# ior7f701057 register map
Registers are 8-bit, access not given, no defined reset value unless marked. A register's access mark holds for its fields unless they carry their own. Addresses are absolute; registers are grouped by the start of their names; [hi:lo] are bit positions; {n}, {i} and the like mark numbered series; 'fields as' and 'values as' point back to an identical list.

## SFR (part 2 of 3)
{0xFFD00E80+0x10*i} RSCAN0CFID{i}LL (i=0..17)
{0xFFD00E81+0x10*i} RSCAN0CFID{i}LH (i=0..17)
{0xFFD00E82+0x10*i} RSCAN0CFID{i}H 16-bit (i=0..17)
{0xFFD00E82+0x10*i} RSCAN0CFID{i}HL (i=0..17)
{0xFFD00E83+0x10*i} RSCAN0CFID{i}HH (i=0..17)
{0xFFD00E84+0x10*i} RSCAN0CFPTR{i} 32-bit (i=0..17)
{0xFFD00E84+0x10*i} RSCAN0CFPTR{i}L 16-bit (i=0..17)
{0xFFD00E84+0x10*i} RSCAN0CFPTR{i}LL (i=0..17)
{0xFFD00E85+0x10*i} RSCAN0CFPTR{i}LH (i=0..17)
{0xFFD00E86+0x10*i} RSCAN0CFPTR{i}H 16-bit (i=0..17)
{0xFFD00E86+0x10*i} RSCAN0CFPTR{i}HL (i=0..17)
{0xFFD00E87+0x10*i} RSCAN0CFPTR{i}HH (i=0..17)
{0xFFD00E88+0x10*i} RSCAN0CFDF{i:02} 32-bit (i=0..9)
{0xFFD00E88+0x10*i} RSCAN0CFDF{i:02}L 16-bit (i=0..9)
{0xFFD00E88+0x10*i} RSCAN0CFDF{i:02}LL (i=0..9)
{0xFFD00E89+0x10*i} RSCAN0CFDF{i:02}LH (i=0..9)
{0xFFD00E8A+0x10*i} RSCAN0CFDF{i:02}H 16-bit (i=0..9)
{0xFFD00E8A+0x10*i} RSCAN0CFDF{i:02}HL (i=0..9)
{0xFFD00E8B+0x10*i} RSCAN0CFDF{i:02}HH (i=0..9)
0xFFD00E8C RSCAN0CFDF10 32-bit
0xFFD00E8C RSCAN0CFDF10L 16-bit
0xFFD00E8C RSCAN0CFDF10LL
0xFFD00E8D RSCAN0CFDF10LH
0xFFD00E8E RSCAN0CFDF10H 16-bit
0xFFD00E8E RSCAN0CFDF10HL
0xFFD00E8F RSCAN0CFDF10HH
0xFFD00E9C RSCAN0CFDF11 32-bit
0xFFD00E9C RSCAN0CFDF11L 16-bit
0xFFD00E9C RSCAN0CFDF11LL
0xFFD00E9D RSCAN0CFDF11LH
0xFFD00E9E RSCAN0CFDF11H 16-bit
0xFFD00E9E RSCAN0CFDF11HL
0xFFD00E9F RSCAN0CFDF11HH
0xFFD00EAC RSCAN0CFDF12 32-bit
0xFFD00EAC RSCAN0CFDF12L 16-bit
0xFFD00EAC RSCAN0CFDF12LL
0xFFD00EAD RSCAN0CFDF12LH
0xFFD00EAE RSCAN0CFDF12H 16-bit
0xFFD00EAE RSCAN0CFDF12HL
0xFFD00EAF RSCAN0CFDF12HH
0xFFD00EBC RSCAN0CFDF13 32-bit
0xFFD00EBC RSCAN0CFDF13L 16-bit
0xFFD00EBC RSCAN0CFDF13LL
0xFFD00EBD RSCAN0CFDF13LH
0xFFD00EBE RSCAN0CFDF13H 16-bit
0xFFD00EBE RSCAN0CFDF13HL
0xFFD00EBF RSCAN0CFDF13HH
0xFFD00ECC RSCAN0CFDF14 32-bit
0xFFD00ECC RSCAN0CFDF14L 16-bit
0xFFD00ECC RSCAN0CFDF14LL
0xFFD00ECD RSCAN0CFDF14LH
0xFFD00ECE RSCAN0CFDF14H 16-bit
0xFFD00ECE RSCAN0CFDF14HL
0xFFD00ECF RSCAN0CFDF14HH
0xFFD00EDC RSCAN0CFDF15 32-bit
0xFFD00EDC RSCAN0CFDF15L 16-bit
0xFFD00EDC RSCAN0CFDF15LL
0xFFD00EDD RSCAN0CFDF15LH
0xFFD00EDE RSCAN0CFDF15H 16-bit
0xFFD00EDE RSCAN0CFDF15HL
0xFFD00EDF RSCAN0CFDF15HH
0xFFD00EEC RSCAN0CFDF16 32-bit
0xFFD00EEC RSCAN0CFDF16L 16-bit
0xFFD00EEC RSCAN0CFDF16LL
0xFFD00EED RSCAN0CFDF16LH
0xFFD00EEE RSCAN0CFDF16H 16-bit
0xFFD00EEE RSCAN0CFDF16HL
0xFFD00EEF RSCAN0CFDF16HH
0xFFD00EFC RSCAN0CFDF17 32-bit
0xFFD00EFC RSCAN0CFDF17L 16-bit
0xFFD00EFC RSCAN0CFDF17LL
0xFFD00EFD RSCAN0CFDF17LH
0xFFD00EFE RSCAN0CFDF17H 16-bit
0xFFD00EFE RSCAN0CFDF17HL
0xFFD00EFF RSCAN0CFDF17HH
0xFFD00F0C RSCAN0CFDF18 32-bit
0xFFD00F0C RSCAN0CFDF18L 16-bit
0xFFD00F0C RSCAN0CFDF18LL
0xFFD00F0D RSCAN0CFDF18LH
0xFFD00F0E RSCAN0CFDF18H 16-bit
0xFFD00F0E RSCAN0CFDF18HL
0xFFD00F0F RSCAN0CFDF18HH
0xFFD00F1C RSCAN0CFDF19 32-bit
0xFFD00F1C RSCAN0CFDF19L 16-bit
0xFFD00F1C RSCAN0CFDF19LL
0xFFD00F1D RSCAN0CFDF19LH
0xFFD00F1E RSCAN0CFDF19H 16-bit
0xFFD00F1E RSCAN0CFDF19HL
0xFFD00F1F RSCAN0CFDF19HH
0xFFD00F28 RSCAN0CFDF010 32-bit
0xFFD00F28 RSCAN0CFDF010L 16-bit
0xFFD00F28 RSCAN0CFDF010LL
0xFFD00F29 RSCAN0CFDF010LH
0xFFD00F2A RSCAN0CFDF010H 16-bit
0xFFD00F2A RSCAN0CFDF010HL
0xFFD00F2B RSCAN0CFDF010HH
{0xFFD0084C+0x10*i} RSCAN0CFDF{i} 32-bit (i=110..117)
{0xFFD0084C+0x10*i} RSCAN0CFDF{i}L 16-bit (i=110..117)
{0xFFD0084C+0x10*i} RSCAN0CFDF{i}LL (i=110..117)
{0xFFD0084D+0x10*i} RSCAN0CFDF{i}LH (i=110..117)
{0xFFD0084E+0x10*i} RSCAN0CFDF{i}H 16-bit (i=110..117)
{0xFFD0084E+0x10*i} RSCAN0CFDF{i}HL (i=110..117)
{0xFFD0084F+0x10*i} RSCAN0CFDF{i}HH (i=110..117)
0xFFD00F38 RSCAN0CFDF011 32-bit
0xFFD00F38 RSCAN0CFDF011L 16-bit
0xFFD00F38 RSCAN0CFDF011LL
0xFFD00F39 RSCAN0CFDF011LH
0xFFD00F3A RSCAN0CFDF011H 16-bit
0xFFD00F3A RSCAN0CFDF011HL
0xFFD00F3B RSCAN0CFDF011HH
0xFFD00F48 RSCAN0CFDF012 32-bit
0xFFD00F48 RSCAN0CFDF012L 16-bit
0xFFD00F48 RSCAN0CFDF012LL
0xFFD00F49 RSCAN0CFDF012LH
0xFFD00F4A RSCAN0CFDF012H 16-bit
0xFFD00F4A RSCAN0CFDF012HL
0xFFD00F4B RSCAN0CFDF012HH
0xFFD00F58 RSCAN0CFDF013 32-bit
0xFFD00F58 RSCAN0CFDF013L 16-bit
0xFFD00F58 RSCAN0CFDF013LL
0xFFD00F59 RSCAN0CFDF013LH
0xFFD00F5A RSCAN0CFDF013H 16-bit
0xFFD00F5A RSCAN0CFDF013HL
0xFFD00F5B RSCAN0CFDF013HH
0xFFD00F68 RSCAN0CFDF014 32-bit
0xFFD00F68 RSCAN0CFDF014L 16-bit
0xFFD00F68 RSCAN0CFDF014LL
0xFFD00F69 RSCAN0CFDF014LH
0xFFD00F6A RSCAN0CFDF014H 16-bit
0xFFD00F6A RSCAN0CFDF014HL
0xFFD00F6B RSCAN0CFDF014HH
0xFFD00F78 RSCAN0CFDF015 32-bit
0xFFD00F78 RSCAN0CFDF015L 16-bit
0xFFD00F78 RSCAN0CFDF015LL
0xFFD00F79 RSCAN0CFDF015LH
0xFFD00F7A RSCAN0CFDF015H 16-bit
0xFFD00F7A RSCAN0CFDF015HL
0xFFD00F7B RSCAN0CFDF015HH
0xFFD00F88 RSCAN0CFDF016 32-bit
0xFFD00F88 RSCAN0CFDF016L 16-bit
0xFFD00F88 RSCAN0CFDF016LL
0xFFD00F89 RSCAN0CFDF016LH
0xFFD00F8A RSCAN0CFDF016H 16-bit
0xFFD00F8A RSCAN0CFDF016HL
0xFFD00F8B RSCAN0CFDF016HH
0xFFD00F98 RSCAN0CFDF017 32-bit
0xFFD00F98 RSCAN0CFDF017L 16-bit
0xFFD00F98 RSCAN0CFDF017LL
0xFFD00F99 RSCAN0CFDF017LH
0xFFD00F9A RSCAN0CFDF017H 16-bit
0xFFD00F9A RSCAN0CFDF017HL
0xFFD00F9B RSCAN0CFDF017HH
{0xFFD01000+0x10*i} RSCAN0TMID{i} 32-bit (i=0..95)
{0xFFD01000+0x10*i} RSCAN0TMID{i}L 16-bit (i=0..95)
{0xFFD01000+0x10*i} RSCAN0TMID{i}LL (i=0..95)
{0xFFD01001+0x10*i} RSCAN0TMID{i}LH (i=0..95)
{0xFFD01002+0x10*i} RSCAN0TMID{i}H 16-bit (i=0..95)
{0xFFD01002+0x10*i} RSCAN0TMID{i}HL (i=0..95)
{0xFFD01003+0x10*i} RSCAN0TMID{i}HH (i=0..95)
{0xFFD01004+0x10*i} RSCAN0TMPTR{i} 32-bit (i=0..95)
{0xFFD01006+0x10*i} RSCAN0TMPTR{i}H 16-bit (i=0..95)
{0xFFD01006+0x10*i} RSCAN0TMPTR{i}HL (i=0..95)
{0xFFD01007+0x10*i} RSCAN0TMPTR{i}HH (i=0..95)
{0xFFD01008+0x10*i} RSCAN0TMDF{i:02} 32-bit (i=0..9)
{0xFFD01008+0x10*i} RSCAN0TMDF{i:02}L 16-bit (i=0..9)
{0xFFD01008+0x10*i} RSCAN0TMDF{i:02}LL (i=0..9)
{0xFFD01009+0x10*i} RSCAN0TMDF{i:02}LH (i=0..9)
{0xFFD0100A+0x10*i} RSCAN0TMDF{i:02}H 16-bit (i=0..9)
{0xFFD0100A+0x10*i} RSCAN0TMDF{i:02}HL (i=0..9)
{0xFFD0100B+0x10*i} RSCAN0TMDF{i:02}HH (i=0..9)
0xFFD0100C RSCAN0TMDF10 32-bit
0xFFD0100C RSCAN0TMDF10L 16-bit
0xFFD0100C RSCAN0TMDF10LL
0xFFD0100D RSCAN0TMDF10LH
0xFFD0100E RSCAN0TMDF10H 16-bit
0xFFD0100E RSCAN0TMDF10HL
0xFFD0100F RSCAN0TMDF10HH
0xFFD0101C RSCAN0TMDF11 32-bit
0xFFD0101C RSCAN0TMDF11L 16-bit
0xFFD0101C RSCAN0TMDF11LL
0xFFD0101D RSCAN0TMDF11LH
0xFFD0101E RSCAN0TMDF11H 16-bit
0xFFD0101E RSCAN0TMDF11HL
0xFFD0101F RSCAN0TMDF11HH
0xFFD0102C RSCAN0TMDF12 32-bit
0xFFD0102C RSCAN0TMDF12L 16-bit
0xFFD0102C RSCAN0TMDF12LL
0xFFD0102D RSCAN0TMDF12LH
0xFFD0102E RSCAN0TMDF12H 16-bit
0xFFD0102E RSCAN0TMDF12HL
0xFFD0102F RSCAN0TMDF12HH
0xFFD0103C RSCAN0TMDF13 32-bit
0xFFD0103C RSCAN0TMDF13L 16-bit
0xFFD0103C RSCAN0TMDF13LL
0xFFD0103D RSCAN0TMDF13LH
0xFFD0103E RSCAN0TMDF13H 16-bit
0xFFD0103E RSCAN0TMDF13HL
0xFFD0103F RSCAN0TMDF13HH
0xFFD0104C RSCAN0TMDF14 32-bit
0xFFD0104C RSCAN0TMDF14L 16-bit
0xFFD0104C RSCAN0TMDF14LL
0xFFD0104D RSCAN0TMDF14LH
0xFFD0104E RSCAN0TMDF14H 16-bit
0xFFD0104E RSCAN0TMDF14HL
0xFFD0104F RSCAN0TMDF14HH
0xFFD0105C RSCAN0TMDF15 32-bit
0xFFD0105C RSCAN0TMDF15L 16-bit
0xFFD0105C RSCAN0TMDF15LL
0xFFD0105D RSCAN0TMDF15LH
0xFFD0105E RSCAN0TMDF15H 16-bit
0xFFD0105E RSCAN0TMDF15HL
0xFFD0105F RSCAN0TMDF15HH
0xFFD0106C RSCAN0TMDF16 32-bit
0xFFD0106C RSCAN0TMDF16L 16-bit
0xFFD0106C RSCAN0TMDF16LL
0xFFD0106D RSCAN0TMDF16LH
0xFFD0106E RSCAN0TMDF16H 16-bit
0xFFD0106E RSCAN0TMDF16HL
0xFFD0106F RSCAN0TMDF16HH
0xFFD0107C RSCAN0TMDF17 32-bit
0xFFD0107C RSCAN0TMDF17L 16-bit
0xFFD0107C RSCAN0TMDF17LL
0xFFD0107D RSCAN0TMDF17LH
0xFFD0107E RSCAN0TMDF17H 16-bit
0xFFD0107E RSCAN0TMDF17HL
0xFFD0107F RSCAN0TMDF17HH
0xFFD0108C RSCAN0TMDF18 32-bit
0xFFD0108C RSCAN0TMDF18L 16-bit
0xFFD0108C RSCAN0TMDF18LL
0xFFD0108D RSCAN0TMDF18LH
0xFFD0108E RSCAN0TMDF18H 16-bit
0xFFD0108E RSCAN0TMDF18HL
0xFFD0108F RSCAN0TMDF18HH
0xFFD0109C RSCAN0TMDF19 32-bit
0xFFD0109C RSCAN0TMDF19L 16-bit
0xFFD0109C RSCAN0TMDF19LL
0xFFD0109D RSCAN0TMDF19LH
0xFFD0109E RSCAN0TMDF19H 16-bit
0xFFD0109E RSCAN0TMDF19HL
0xFFD0109F RSCAN0TMDF19HH
0xFFD010A8 RSCAN0TMDF010 32-bit
0xFFD010A8 RSCAN0TMDF010L 16-bit
0xFFD010A8 RSCAN0TMDF010LL
0xFFD010A9 RSCAN0TMDF010LH
0xFFD010AA RSCAN0TMDF010H 16-bit
0xFFD010AA RSCAN0TMDF010HL
0xFFD010AB RSCAN0TMDF010HH
{0xFFD009CC+0x10*i} RSCAN0TMDF{i} 32-bit (i=110..195)
{0xFFD009CC+0x10*i} RSCAN0TMDF{i}L 16-bit (i=110..195)
{0xFFD009CC+0x10*i} RSCAN0TMDF{i}LL (i=110..195)
{0xFFD009CD+0x10*i} RSCAN0TMDF{i}LH (i=110..195)
{0xFFD009CE+0x10*i} RSCAN0TMDF{i}H 16-bit (i=110..195)
{0xFFD009CE+0x10*i} RSCAN0TMDF{i}HL (i=110..195)
{0xFFD009CF+0x10*i} RSCAN0TMDF{i}HH (i=110..195)
0xFFD010B8 RSCAN0TMDF011 32-bit
0xFFD010B8 RSCAN0TMDF011L 16-bit
0xFFD010B8 RSCAN0TMDF011LL
0xFFD010B9 RSCAN0TMDF011LH
0xFFD010BA RSCAN0TMDF011H 16-bit
0xFFD010BA RSCAN0TMDF011HL
0xFFD010BB RSCAN0TMDF011HH
0xFFD010C8 RSCAN0TMDF012 32-bit
0xFFD010C8 RSCAN0TMDF012L 16-bit
0xFFD010C8 RSCAN0TMDF012LL
0xFFD010C9 RSCAN0TMDF012LH
0xFFD010CA RSCAN0TMDF012H 16-bit
0xFFD010CA RSCAN0TMDF012HL
0xFFD010CB RSCAN0TMDF012HH
0xFFD010D8 RSCAN0TMDF013 32-bit
0xFFD010D8 RSCAN0TMDF013L 16-bit
0xFFD010D8 RSCAN0TMDF013LL
0xFFD010D9 RSCAN0TMDF013LH
0xFFD010DA RSCAN0TMDF013H 16-bit
0xFFD010DA RSCAN0TMDF013HL
0xFFD010DB RSCAN0TMDF013HH
0xFFD010E8 RSCAN0TMDF014 32-bit
0xFFD010E8 RSCAN0TMDF014L 16-bit
0xFFD010E8 RSCAN0TMDF014LL
0xFFD010E9 RSCAN0TMDF014LH
0xFFD010EA RSCAN0TMDF014H 16-bit
0xFFD010EA RSCAN0TMDF014HL
0xFFD010EB RSCAN0TMDF014HH
0xFFD010F8 RSCAN0TMDF015 32-bit
0xFFD010F8 RSCAN0TMDF015L 16-bit
0xFFD010F8 RSCAN0TMDF015LL
0xFFD010F9 RSCAN0TMDF015LH
0xFFD010FA RSCAN0TMDF015H 16-bit
0xFFD010FA RSCAN0TMDF015HL
0xFFD010FB RSCAN0TMDF015HH
0xFFD01108 RSCAN0TMDF016 32-bit
0xFFD01108 RSCAN0TMDF016L 16-bit
0xFFD01108 RSCAN0TMDF016LL
0xFFD01109 RSCAN0TMDF016LH
0xFFD0110A RSCAN0TMDF016H 16-bit
0xFFD0110A RSCAN0TMDF016HL
0xFFD0110B RSCAN0TMDF016HH
0xFFD01118 RSCAN0TMDF017 32-bit
0xFFD01118 RSCAN0TMDF017L 16-bit
0xFFD01118 RSCAN0TMDF017LL
0xFFD01119 RSCAN0TMDF017LH
0xFFD0111A RSCAN0TMDF017H 16-bit
0xFFD0111A RSCAN0TMDF017HL
0xFFD0111B RSCAN0TMDF017HH
0xFFD01128 RSCAN0TMDF018 32-bit
0xFFD01128 RSCAN0TMDF018L 16-bit
0xFFD01128 RSCAN0TMDF018LL
0xFFD01129 RSCAN0TMDF018LH
0xFFD0112A RSCAN0TMDF018H 16-bit
0xFFD0112A RSCAN0TMDF018HL
0xFFD0112B RSCAN0TMDF018HH
{0xFFD01008+0x10*i} RSCAN0TMDF{i:03} 32-bit (i=19..95)
{0xFFD01008+0x10*i} RSCAN0TMDF{i:03}L 16-bit (i=19..95)
{0xFFD01008+0x10*i} RSCAN0TMDF{i:03}LL (i=19..95)
{0xFFD01009+0x10*i} RSCAN0TMDF{i:03}LH (i=19..95)
{0xFFD0100A+0x10*i} RSCAN0TMDF{i:03}H 16-bit (i=19..95)
{0xFFD0100A+0x10*i} RSCAN0TMDF{i:03}HL (i=19..95)
{0xFFD0100B+0x10*i} RSCAN0TMDF{i:03}HH (i=19..95)
{0xFFD01800+4i} RSCAN0THLACC{i} 32-bit ro (i=0..5)
{0xFFD01800+4i} RSCAN0THLACC{i}L 16-bit ro (i=0..5)
{0xFFD01800+4i} RSCAN0THLACC{i}LL ro (i=0..5)
{0xFFD01801+4i} RSCAN0THLACC{i}LH ro (i=0..5)
{0xFFD01900+4i} RSCAN0RPGACC{i} 32-bit (i=0..63)
{0xFFD01900+4i} RSCAN0RPGACC{i}L 16-bit (i=0..63)
{0xFFD01900+4i} RSCAN0RPGACC{i}LL (i=0..63)
{0xFFD01901+4i} RSCAN0RPGACC{i}LH (i=0..63)
{0xFFD01902+4i} RSCAN0RPGACC{i}H 16-bit (i=0..63)
{0xFFD01902+4i} RSCAN0RPGACC{i}HL (i=0..63)
{0xFFD01903+4i} RSCAN0RPGACC{i}HH (i=0..63)
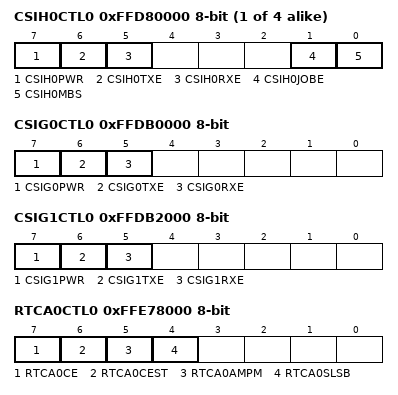
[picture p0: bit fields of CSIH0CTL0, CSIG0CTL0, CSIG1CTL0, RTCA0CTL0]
{0xFFD80000+0x2000*i} CSIH{i}CTL0 (i=0..3)
  [7] CSIH{i}PWR, [6] CSIH{i}TXE, [5] CSIH{i}RXE, [1] CSIH{i}JOBE, [0] CSIH{i}MBS
{0xFFD80004+0x2000*i} CSIH{i}STR0 32-bit ro (i=0..3)
{0xFFD80008+0x2000*i} CSIH{i}STCR0 16-bit (i=0..3)
{0xFFD80010+0x2000*i} CSIH{i}CTL1 32-bit (i=0..3)
{0xFFD80014+0x2000*i} CSIH{i}CTL2 16-bit (i=0..3)
{0xFFD80018+0x2000*i} CSIH{i}EMU (i=0..3)
  [7] CSIH{i}SVSDIS
{0xFFD81000+0x2000*i} CSIH{i}MCTL1 32-bit (i=0..3)
{0xFFD81004+0x2000*i} CSIH{i}MCTL2 32-bit (i=0..3)
{0xFFD81008+0x2000*i} CSIH{i}TX0W 32-bit (i=0..3)
{0xFFD8100C+0x2000*i} CSIH{i}TX0H 16-bit (i=0..3)
{0xFFD81010+0x2000*i} CSIH{i}RX0W 32-bit ro (i=0..3)
{0xFFD81014+0x2000*i} CSIH{i}RX0H 16-bit ro (i=0..3)
{0xFFD81018+0x2000*i} CSIH{i}MRWP0 32-bit (i=0..3)
{0xFFD81040+0x2000*i} CSIH{i}MCTL0 16-bit (i=0..3)
{0xFFD81044+4i} CSIH0CFG{i} 32-bit (i=0..7)
{0xFFD81068+0x2000*i} CSIH{i}BRS0 16-bit (i=0..3)
{0xFFD8106C+0x2000*i} CSIH{i}BRS1 16-bit (i=0..3)
{0xFFD81070+0x2000*i} CSIH{i}BRS2 16-bit (i=0..3)
{0xFFD81074+0x2000*i} CSIH{i}BRS3 16-bit (i=0..3)
{0xFFD83044+4i} CSIH1CFG{i} 32-bit (i=0..5)
{0xFFD85044+4i} CSIH2CFG{i} 32-bit (i=0..5)
{0xFFD87044+4i} CSIH3CFG{i} 32-bit (i=0..3)
0xFFDB0000 CSIG0CTL0
  [7] CSIG0PWR, [6] CSIG0TXE, [5] CSIG0RXE
0xFFDB0004 CSIG0STR0 32-bit ro
0xFFDB0008 CSIG0STCR0 16-bit
0xFFDB0010 CSIG0CTL1 32-bit
0xFFDB0014 CSIG0CTL2 16-bit
0xFFDB0018 CSIG0EMU
  [7] CSIG0SVSDIS
0xFFDB1000 CSIG0BCTL0
  [0] CSIG0SCE
0xFFDB1004 CSIG0TX0W 32-bit
0xFFDB1008 CSIG0TX0H 16-bit
0xFFDB100C CSIG0RX0 16-bit ro
0xFFDB1010 CSIG0CFG0 32-bit
0xFFDB2000 CSIG1CTL0
  [7] CSIG1PWR, [6] CSIG1TXE, [5] CSIG1RXE
0xFFDB2004 CSIG1STR0 32-bit ro
0xFFDB2008 CSIG1STCR0 16-bit
0xFFDB2010 CSIG1CTL1 32-bit
0xFFDB2014 CSIG1CTL2 16-bit
0xFFDB2018 CSIG1EMU
  [7] CSIG1SVSDIS
0xFFDB3000 CSIG1BCTL0
  [0] CSIG1SCE
0xFFDB3004 CSIG1TX0W 32-bit
0xFFDB3008 CSIG1TX0H 16-bit
0xFFDB300C CSIG1RX0 16-bit ro
0xFFDB3010 CSIG1CFG0 32-bit
0xFFDD0004 PIC0SST wo
0xFFDD0010 PIC0SSER0 16-bit
0xFFDD0018 PIC0SSER2 16-bit
0xFFDD0080 PIC0HIZCEN0
{0xFFDCFA50+4i} PIC0ADTEN{i} 16-bit (i=400..402)
{0xFFDCFDA0+4i} PIC0REG{i} 32-bit (i=200..203)
0xFFDD00E8 PIC0REG30 32-bit
0xFFDD00EC PIC0REG31 32-bit
{0xFFE20000+4i} TAUD0CDR{i} 16-bit (i=0..15)
0xFFE20040 TAUD0TOL 16-bit
0xFFE20044 TAUD0RDT 16-bit wo
0xFFE20048 TAUD0RSF 16-bit ro
0xFFE2004C TAUD0TRO 16-bit
0xFFE20050 TAUD0TME 16-bit
0xFFE20054 TAUD0TDL 16-bit
0xFFE20058 TAUD0TO 16-bit
0xFFE2005C TAUD0TOE 16-bit
{0xFFE20080+4i} TAUD0CNT{i} 16-bit ro (i=0..15)
{0xFFE200C0+4i} TAUD0CMUR{i} (i=0..15)
{0xFFE20140+4i} TAUD0CSR{i} ro (i=0..15)
{0xFFE20180+4i} TAUD0CSC{i} wo (i=0..15)
0xFFE201C0 TAUD0TE 16-bit ro
0xFFE201C4 TAUD0TS 16-bit wo
0xFFE201C8 TAUD0TT 16-bit wo
{0xFFE20200+4i} TAUD0CMOR{i} 16-bit (i=0..15)
0xFFE20240 TAUD0TPS 16-bit
0xFFE20244 TAUD0BRS
0xFFE20248 TAUD0TOM 16-bit
0xFFE2024C TAUD0TOC 16-bit
0xFFE20250 TAUD0TDE 16-bit
0xFFE20254 TAUD0TDM 16-bit
0xFFE20258 TAUD0TRE 16-bit
0xFFE2025C TAUD0TRC 16-bit
0xFFE20260 TAUD0RDE 16-bit
0xFFE20264 TAUD0RDM 16-bit
0xFFE20268 TAUD0RDS 16-bit
0xFFE2026C TAUD0RDC 16-bit
0xFFE20290 TAUD0EMU
{0xFFE30000+4i} TAUB0CDR{i} 16-bit (i=0..15)
0xFFE30040 TAUB0TOL 16-bit
0xFFE30044 TAUB0RDT 16-bit wo
0xFFE30048 TAUB0RSF 16-bit ro
0xFFE30054 TAUB0TDL 16-bit
0xFFE30058 TAUB0TO 16-bit
0xFFE3005C TAUB0TOE 16-bit
{0xFFE30080+4i} TAUB0CNT{i} 16-bit ro (i=0..15)
{0xFFE300C0+4i} TAUB0CMUR{i} (i=0..15)
{0xFFE30140+4i} TAUB0CSR{i} ro (i=0..15)
{0xFFE30180+4i} TAUB0CSC{i} wo (i=0..15)
0xFFE301C0 TAUB0TE 16-bit ro
0xFFE301C4 TAUB0TS 16-bit wo
0xFFE301C8 TAUB0TT 16-bit wo
{0xFFE30200+4i} TAUB0CMOR{i} 16-bit (i=0..15)
0xFFE30240 TAUB0TPS 16-bit
0xFFE30248 TAUB0TOM 16-bit
0xFFE3024C TAUB0TOC 16-bit
0xFFE30250 TAUB0TDE 16-bit
0xFFE30260 TAUB0RDE 16-bit
0xFFE30264 TAUB0RDM 16-bit
0xFFE30268 TAUB0RDS 16-bit
0xFFE3026C TAUB0RDC 16-bit
0xFFE30290 TAUB0EMU
{0xFFE31000+4i} TAUB1CDR{i} 16-bit (i=0..15)
0xFFE31040 TAUB1TOL 16-bit
0xFFE31044 TAUB1RDT 16-bit wo
0xFFE31048 TAUB1RSF 16-bit ro
0xFFE31054 TAUB1TDL 16-bit
0xFFE31058 TAUB1TO 16-bit
0xFFE3105C TAUB1TOE 16-bit
{0xFFE31080+4i} TAUB1CNT{i} 16-bit ro (i=0..15)
{0xFFE310C0+4i} TAUB1CMUR{i} (i=0..15)
{0xFFE31140+4i} TAUB1CSR{i} ro (i=0..15)
{0xFFE31180+4i} TAUB1CSC{i} wo (i=0..15)
0xFFE311C0 TAUB1TE 16-bit ro
0xFFE311C4 TAUB1TS 16-bit wo
0xFFE311C8 TAUB1TT 16-bit wo
{0xFFE31200+4i} TAUB1CMOR{i} 16-bit (i=0..15)
0xFFE31240 TAUB1TPS 16-bit
0xFFE31248 TAUB1TOM 16-bit
0xFFE3124C TAUB1TOC 16-bit
0xFFE31250 TAUB1TDE 16-bit
0xFFE31260 TAUB1RDE 16-bit
0xFFE31264 TAUB1RDM 16-bit
0xFFE31268 TAUB1RDS 16-bit
0xFFE3126C TAUB1RDC 16-bit
0xFFE31290 TAUB1EMU
{0xFFE50000+4i} TAUJ0CDR{i} 32-bit (i=0..3)
{0xFFE50010+4i} TAUJ0CNT{i} 32-bit ro (i=0..3)
{0xFFE50020+4i} TAUJ0CMUR{i} (i=0..3)
{0xFFE50030+4i} TAUJ0CSR{i} ro (i=0..3)
{0xFFE50040+4i} TAUJ0CSC{i} wo (i=0..3)
0xFFE50050 TAUJ0TE ro
0xFFE50054 TAUJ0TS wo
0xFFE50058 TAUJ0TT wo
0xFFE5005C TAUJ0TO
0xFFE50060 TAUJ0TOE
0xFFE50064 TAUJ0TOL
0xFFE50068 TAUJ0RDT wo
0xFFE5006C TAUJ0RSF ro
{0xFFE50080+4i} TAUJ0CMOR{i} 16-bit (i=0..3)
0xFFE50090 TAUJ0TPS 16-bit
0xFFE50094 TAUJ0BRS
0xFFE50098 TAUJ0TOM
0xFFE5009C TAUJ0TOC
0xFFE500A0 TAUJ0RDE
0xFFE500A4 TAUJ0RDM
0xFFE500A8 TAUJ0EMU
{0xFFE51000+4i} TAUJ1CDR{i} 32-bit (i=0..3)
{0xFFE51010+4i} TAUJ1CNT{i} 32-bit ro (i=0..3)
{0xFFE51020+4i} TAUJ1CMUR{i} (i=0..3)
{0xFFE51030+4i} TAUJ1CSR{i} ro (i=0..3)
{0xFFE51040+4i} TAUJ1CSC{i} wo (i=0..3)
0xFFE51050 TAUJ1TE ro
0xFFE51054 TAUJ1TS wo
0xFFE51058 TAUJ1TT wo
0xFFE5105C TAUJ1TO
0xFFE51060 TAUJ1TOE
0xFFE51064 TAUJ1TOL
0xFFE51068 TAUJ1RDT wo
0xFFE5106C TAUJ1RSF ro
{0xFFE51080+4i} TAUJ1CMOR{i} 16-bit (i=0..3)
0xFFE51090 TAUJ1TPS 16-bit
0xFFE51094 TAUJ1BRS
0xFFE51098 TAUJ1TOM
0xFFE5109C TAUJ1TOC
0xFFE510A0 TAUJ1RDE
0xFFE510A4 TAUJ1RDM
0xFFE510A8 TAUJ1EMU
0xFFE70000 PWSA0CTL
0xFFE70004 PWSA0STR ro
0xFFE70008 PWSA0STC wo
0xFFE7000C PWSA0EMU
{0xFFE70020+4i} PWSA0QUE{i} ro (i=0..7)
0xFFE70040 PWSA0PVCR00_01 32-bit
0xFFE70044 PWSA0PVCR02_03 32-bit
0xFFE70048 PWSA0PVCR04_05 32-bit
0xFFE7004C PWSA0PVCR06_07 32-bit
0xFFE70050 PWSA0PVCR08_09 32-bit
0xFFE70054 PWSA0PVCR10_11 32-bit
0xFFE70058 PWSA0PVCR12_13 32-bit
0xFFE7005C PWSA0PVCR14_15 32-bit
0xFFE70060 PWSA0PVCR16_17 32-bit
0xFFE70064 PWSA0PVCR18_19 32-bit
0xFFE70068 PWSA0PVCR20_21 32-bit
0xFFE7006C PWSA0PVCR22_23 32-bit
0xFFE70070 PWSA0PVCR24_25 32-bit
0xFFE70074 PWSA0PVCR26_27 32-bit
0xFFE70078 PWSA0PVCR28_29 32-bit
0xFFE7007C PWSA0PVCR30_31 32-bit
0xFFE70080 PWSA0PVCR32_33 32-bit
0xFFE70084 PWSA0PVCR34_35 32-bit
0xFFE70088 PWSA0PVCR36_37 32-bit
0xFFE7008C PWSA0PVCR38_39 32-bit
0xFFE70090 PWSA0PVCR40_41 32-bit
0xFFE70094 PWSA0PVCR42_43 32-bit
0xFFE70098 PWSA0PVCR44_45 32-bit
0xFFE7009C PWSA0PVCR46_47 32-bit
0xFFE700A0 PWSA0PVCR48_49 32-bit
0xFFE700A4 PWSA0PVCR50_51 32-bit
0xFFE700A8 PWSA0PVCR52_53 32-bit
0xFFE700AC PWSA0PVCR54_55 32-bit
0xFFE700B0 PWSA0PVCR56_57 32-bit
0xFFE700B4 PWSA0PVCR58_59 32-bit
0xFFE700B8 PWSA0PVCR60_61 32-bit
0xFFE700BC PWSA0PVCR62_63 32-bit
0xFFE700C0 PWSA0PVCR64_65 32-bit
0xFFE700C4 PWSA0PVCR66_67 32-bit
0xFFE700C8 PWSA0PVCR68_69 32-bit
0xFFE700CC PWSA0PVCR70_71 32-bit
{0xFFE71000+0x40*i} PWGA{i}CSDR 16-bit (i=0..71)
{0xFFE71004+0x40*i} PWGA{i}CRDR 16-bit (i=0..71)
{0xFFE71008+0x40*i} PWGA{i}CTDR 16-bit (i=0..71)
{0xFFE7100C+0x40*i} PWGA{i}RDT wo (i=0..71)
{0xFFE71010+0x40*i} PWGA{i}RSF ro (i=0..71)
{0xFFE71014+0x40*i} PWGA{i}CNT 16-bit ro (i=0..71)
{0xFFE71020+0x40*i} PWGA{i}CTL (i=0..71)
{0xFFE71024+0x40*i} PWGA{i}CSBR 16-bit ro (i=0..71)
{0xFFE71028+0x40*i} PWGA{i}CRBR 16-bit ro (i=0..71)
{0xFFE7102C+0x40*i} PWGA{i}CTBR 16-bit ro (i=0..71)
{0xFFE72800+4i} PWBA0BRS{i} 16-bit (i=0..3)
0xFFE72810 PWBA0TE ro
0xFFE72814 PWBA0TS wo
0xFFE72818 PWBA0TT wo
0xFFE7281C PWBA0EMU
0xFFE78000 RTCA0CTL0
  [7] RTCA0CE, [6] RTCA0CEST ro, [5] RTCA0AMPM, [4] RTCA0SLSB
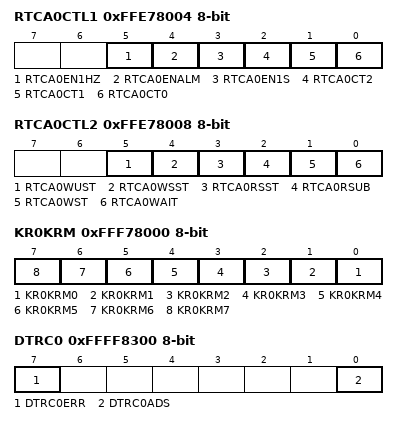
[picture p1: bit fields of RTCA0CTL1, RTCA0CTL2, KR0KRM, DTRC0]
0xFFE78004 RTCA0CTL1
  [5] RTCA0EN1HZ, [4] RTCA0ENALM, [3] RTCA0EN1S, [2] RTCA0CT2, [1] RTCA0CT1, [0] RTCA0CT0
0xFFE78008 RTCA0CTL2
  [5] RTCA0WUST ro, [4] RTCA0WSST ro, [3] RTCA0RSST ro, [2] RTCA0RSUB, [1] RTCA0WST ro, [0] RTCA0WAIT
0xFFE7800C RTCA0SUBC 32-bit ro
0xFFE78010 RTCA0SRBU 32-bit ro
0xFFE78014 RTCA0SEC
0xFFE78018 RTCA0MIN
0xFFE7801C RTCA0HOUR
0xFFE78020 RTCA0WEEK
0xFFE78024 RTCA0DAY
0xFFE78028 RTCA0MONTH
0xFFE7802C RTCA0YEAR
0xFFE78030 RTCA0TIME 32-bit
0xFFE78034 RTCA0CAL 32-bit
0xFFE78038 RTCA0SUBU
0xFFE7803C RTCA0SCMP 32-bit
0xFFE78040 RTCA0ALM
0xFFE78044 RTCA0ALH
0xFFE78048 RTCA0ALW
0xFFE7804C RTCA0SECC ro
0xFFE78050 RTCA0MINC ro
0xFFE78054 RTCA0HOURC ro
0xFFE78058 RTCA0WEEKC ro
0xFFE7805C RTCA0DAYC ro
0xFFE78060 RTCA0MONC ro
0xFFE78064 RTCA0YEARC ro
0xFFE78068 RTCA0TIMEC 32-bit ro
0xFFE7806C RTCA0CALC 32-bit ro
0xFFE78074 RTCA0EMU
  [7] RTCA0SVSDIS
0xFFE80000 ENCA0CCR0 16-bit
0xFFE80004 ENCA0CCR1 16-bit
0xFFE80008 ENCA0CNT 16-bit
0xFFE8000C ENCA0FLG ro
0xFFE80010 ENCA0FGC wo
0xFFE80014 ENCA0TE ro
0xFFE80018 ENCA0TS wo
0xFFE8001C ENCA0TT wo
0xFFE80020 ENCA0IOC0
0xFFE80040 ENCA0CTL 16-bit
0xFFE80044 ENCA0IOC1
0xFFE80048 ENCA0EMU
0xFFE90000 TAPA0FLG 16-bit ro
0xFFE90004 TAPA0ACWE
0xFFE90008 TAPA0ACTS wo
0xFFE9000C TAPA0ACTT wo
0xFFE90014 TAPA0OPHS wo
0xFFE90018 TAPA0OPHT wo
0xFFE90020 TAPA0CTL0 16-bit
0xFFE90024 TAPA0CTL1
0xFFE90028 TAPA0EMU
0xFFEC0000 OSTM0CMP 32-bit
0xFFEC0004 OSTM0CNT 32-bit ro
0xFFEC0010 OSTM0TE ro
0xFFEC0014 OSTM0TS wo
0xFFEC0018 OSTM0TT wo
0xFFEC0020 OSTM0CTL
0xFFEC0024 OSTM0EMU
0xFFED0000 WDTA0WDTE
0xFFED0004 WDTA0EVAC
0xFFED0008 WDTA0REF ro
0xFFED000C WDTA0MD
0xFFED1000 WDTA1WDTE
0xFFED1004 WDTA1EVAC
0xFFED1008 WDTA1REF ro
0xFFED100C WDTA1MD
{0xFFF20000+4i} ADCA0VCR{i:02} 32-bit (i=0..49)
{0xFFF20000+4i} ADCA0VCR{i:02}L 16-bit (i=0..49)
{0xFFF20000+4i} ADCA0VCR{i:02}LL (i=0..49)
{0xFFF20001+4i} ADCA0VCR{i:02}LH (i=0..49)
0xFFF200F4 ADCA0PWDVCR 32-bit ro
0xFFF200F4 ADCA0PWDVCRL 16-bit ro
0xFFF200F4 ADCA0PWDVCRLL ro
0xFFF200F5 ADCA0PWDVCRLH ro
0xFFF20100 ADCA0DR00 32-bit ro
0xFFF20100 ADCA0DR00L 16-bit ro
0xFFF20102 ADCA0DR00H 16-bit ro
0xFFF20104 ADCA0DR02 32-bit ro
0xFFF20104 ADCA0DR02L 16-bit ro
0xFFF20106 ADCA0DR02H 16-bit ro
0xFFF20108 ADCA0DR04 32-bit ro
0xFFF20108 ADCA0DR04L 16-bit ro
0xFFF2010A ADCA0DR04H 16-bit ro
0xFFF2010C ADCA0DR06 32-bit ro
0xFFF2010C ADCA0DR06L 16-bit ro
0xFFF2010E ADCA0DR06H 16-bit ro
0xFFF20110 ADCA0DR08 32-bit ro
0xFFF20110 ADCA0DR08L 16-bit ro
0xFFF20112 ADCA0DR08H 16-bit ro
0xFFF20114 ADCA0DR10 32-bit ro
0xFFF20114 ADCA0DR10L 16-bit ro
0xFFF20116 ADCA0DR10H 16-bit ro
0xFFF20118 ADCA0DR12 32-bit ro
0xFFF20118 ADCA0DR12L 16-bit ro
0xFFF2011A ADCA0DR12H 16-bit ro
0xFFF2011C ADCA0DR14 32-bit ro
0xFFF2011C ADCA0DR14L 16-bit ro
0xFFF2011E ADCA0DR14H 16-bit ro
0xFFF20120 ADCA0DR16 32-bit ro
0xFFF20120 ADCA0DR16L 16-bit ro
0xFFF20122 ADCA0DR16H 16-bit ro
0xFFF20124 ADCA0DR18 32-bit ro
0xFFF20124 ADCA0DR18L 16-bit ro
0xFFF20126 ADCA0DR18H 16-bit ro
0xFFF20128 ADCA0DR20 32-bit ro
0xFFF20128 ADCA0DR20L 16-bit ro
0xFFF2012A ADCA0DR20H 16-bit ro
0xFFF2012C ADCA0DR22 32-bit ro
0xFFF2012C ADCA0DR22L 16-bit ro
0xFFF2012E ADCA0DR22H 16-bit ro
0xFFF20130 ADCA0DR24 32-bit ro
0xFFF20130 ADCA0DR24L 16-bit ro
0xFFF20132 ADCA0DR24H 16-bit ro
0xFFF20134 ADCA0DR26 32-bit ro
0xFFF20134 ADCA0DR26L 16-bit ro
0xFFF20136 ADCA0DR26H 16-bit ro
0xFFF20138 ADCA0DR28 32-bit ro
0xFFF20138 ADCA0DR28L 16-bit ro
0xFFF2013A ADCA0DR28H 16-bit ro
0xFFF2013C ADCA0DR30 32-bit ro
0xFFF2013C ADCA0DR30L 16-bit ro
0xFFF2013E ADCA0DR30H 16-bit ro
0xFFF20140 ADCA0DR32 32-bit ro
0xFFF20140 ADCA0DR32L 16-bit ro
0xFFF20142 ADCA0DR32H 16-bit ro
0xFFF20144 ADCA0DR34 32-bit ro
0xFFF20144 ADCA0DR34L 16-bit ro
0xFFF20146 ADCA0DR34H 16-bit ro
0xFFF20148 ADCA0DR36 32-bit ro
0xFFF20148 ADCA0DR36L 16-bit ro
0xFFF2014A ADCA0DR36H 16-bit ro
0xFFF2014C ADCA0DR38 32-bit ro
0xFFF2014C ADCA0DR38L 16-bit ro
0xFFF2014E ADCA0DR38H 16-bit ro
0xFFF20150 ADCA0DR40 32-bit ro
0xFFF20150 ADCA0DR40L 16-bit ro
0xFFF20152 ADCA0DR40H 16-bit ro
0xFFF20154 ADCA0DR42 32-bit ro
0xFFF20154 ADCA0DR42L 16-bit ro
0xFFF20156 ADCA0DR42H 16-bit ro
0xFFF20158 ADCA0DR44 32-bit ro
0xFFF20158 ADCA0DR44L 16-bit ro
0xFFF2015A ADCA0DR44H 16-bit ro
0xFFF2015C ADCA0DR46 32-bit ro
0xFFF2015C ADCA0DR46L 16-bit ro
0xFFF2015E ADCA0DR46H 16-bit ro
0xFFF20160 ADCA0DR48 32-bit ro
0xFFF20160 ADCA0DR48L 16-bit ro
0xFFF20162 ADCA0DR48H 16-bit ro
0xFFF20178 ADCA0PWDTSNDR 32-bit ro
0xFFF2017A ADCA0PWDTSNDRH 16-bit ro
{0xFFF20200+4i} ADCA0DIR{i:02} 32-bit ro (i=0..49)
0xFFF202F4 ADCA0PWDDIR 32-bit ro
0xFFF20300 ADCA0ADHALTR 32-bit wo
0xFFF20300 ADCA0ADHALTRL 16-bit wo
0xFFF20300 ADCA0ADHALTRLL wo
0xFFF20304 ADCA0ADCR 32-bit
0xFFF20304 ADCA0ADCRL 16-bit
0xFFF20304 ADCA0ADCRLL
0xFFF20308 ADCA0SGSTR 32-bit ro
0xFFF20308 ADCA0SGSTRL 16-bit ro
0xFFF2030C ADCA0MPXCURR 32-bit ro
0xFFF2030C ADCA0MPXCURRL 16-bit ro
0xFFF2030C ADCA0MPXCURRLL ro
0xFFF20314 ADCA0THSMPSTCR 32-bit wo
0xFFF20314 ADCA0THSMPSTCRL 16-bit wo
0xFFF20314 ADCA0THSMPSTCRLL wo
0xFFF20318 ADCA0THCR 32-bit
0xFFF20318 ADCA0THCRL 16-bit
0xFFF20318 ADCA0THCRLL
0xFFF2031C ADCA0THAHLDSTCR 32-bit wo
0xFFF2031C ADCA0THAHLDSTCRL 16-bit wo
0xFFF2031C ADCA0THAHLDSTCRLL wo
0xFFF20320 ADCA0THBHLDSTCR 32-bit wo
0xFFF20320 ADCA0THBHLDSTCRL 16-bit wo
0xFFF20320 ADCA0THBHLDSTCRLL wo
0xFFF20324 ADCA0THACR 32-bit
0xFFF20324 ADCA0THACRL 16-bit
0xFFF20324 ADCA0THACRLL
0xFFF20328 ADCA0THBCR 32-bit
0xFFF20328 ADCA0THBCRL 16-bit
0xFFF20328 ADCA0THBCRLL
0xFFF2032C ADCA0THER 32-bit
0xFFF2032C ADCA0THERL 16-bit
0xFFF2032C ADCA0THERLL
0xFFF20330 ADCA0THGSR 32-bit
0xFFF20330 ADCA0THGSRL 16-bit
0xFFF20330 ADCA0THGSRLL
0xFFF20334 ADCA0SFTCR 32-bit
0xFFF20334 ADCA0SFTCRL 16-bit
0xFFF20334 ADCA0SFTCRLL
{0xFFF20338+4i} ADCA0ULLMTBR{i} 32-bit (i=0..2)
{0xFFF20338+4i} ADCA0ULLMTBR{i}L 16-bit (i=0..2)
{0xFFF2033A+4i} ADCA0ULLMTBR{i}H 16-bit (i=0..2)
0xFFF20344 ADCA0ECR 32-bit wo
0xFFF20344 ADCA0ECRL 16-bit wo
0xFFF20344 ADCA0ECRLL wo
0xFFF20348 ADCA0ULER 32-bit ro
0xFFF20348 ADCA0ULERL 16-bit ro
0xFFF20348 ADCA0ULERLL ro
0xFFF20349 ADCA0ULERLH ro
0xFFF2034C ADCA0OWER 32-bit ro
0xFFF2034C ADCA0OWERL 16-bit ro
0xFFF2034C ADCA0OWERLL ro
0xFFF20350 ADCA0DGCTL0 32-bit
0xFFF20350 ADCA0DGCTL0L 16-bit
0xFFF20350 ADCA0DGCTL0LL
0xFFF20354 ADCA0DGCTL1 32-bit
0xFFF20354 ADCA0DGCTL1L 16-bit
0xFFF20358 ADCA0PDCTL1 32-bit
0xFFF20358 ADCA0PDCTL1L 16-bit
0xFFF2035C ADCA0PDCTL2 32-bit
0xFFF2035C ADCA0PDCTL2L 16-bit
0xFFF2035C ADCA0PDCTL2LL
0xFFF2035D ADCA0PDCTL2LH
0xFFF2035E ADCA0PDCTL2H 16-bit
0xFFF2035E ADCA0PDCTL2HL
0xFFF20380 ADCA0SMPCR 32-bit
0xFFF20380 ADCA0SMPCRL 16-bit
0xFFF20380 ADCA0SMPCRLL
0xFFF20388 ADCA0EMU
{0xFFF20400+0x40*i} ADCA0SGSTCR{i} 32-bit wo (i=1..3)
{0xFFF20400+0x40*i} ADCA0SGSTCR{i}L 16-bit wo (i=1..3)
{0xFFF20400+0x40*i} ADCA0SGSTCR{i}LL wo (i=1..3)
{0xFFF20408+0x40*i} ADCA0SGCR{i} 32-bit (i=1..3)
{0xFFF20408+0x40*i} ADCA0SGCR{i}L 16-bit (i=1..3)
{0xFFF20408+0x40*i} ADCA0SGCR{i}LL (i=1..3)
{0xFFF2040C+0x40*i} ADCA0SGVCSP{i} 32-bit (i=1..3)
{0xFFF2040C+0x40*i} ADCA0SGVCSP{i}L 16-bit (i=1..3)
{0xFFF2040C+0x40*i} ADCA0SGVCSP{i}LL (i=1..3)
{0xFFF20410+0x40*i} ADCA0SGVCEP{i} 32-bit (i=1..3)
{0xFFF20410+0x40*i} ADCA0SGVCEP{i}L 16-bit (i=1..3)
{0xFFF20410+0x40*i} ADCA0SGVCEP{i}LL (i=1..3)
{0xFFF20414+0x40*i} ADCA0SGMCYCR{i} 32-bit (i=1..3)
{0xFFF20414+0x40*i} ADCA0SGMCYCR{i}L 16-bit (i=1..3)
{0xFFF20414+0x40*i} ADCA0SGMCYCR{i}LL (i=1..3)
{0xFFF20418+0x40*i} ADCA0SGSEFCR{i} 32-bit wo (i=1..3)
{0xFFF20418+0x40*i} ADCA0SGSEFCR{i}L 16-bit wo (i=1..3)
{0xFFF20418+0x40*i} ADCA0SGSEFCR{i}LL wo (i=1..3)
{0xFFF2041C+0x40*i} ADCA0SGTSEL{i} 32-bit (i=1..3)
{0xFFF2041C+0x40*i} ADCA0SGTSEL{i}L 16-bit (i=1..3)
0xFFF20508 ADCA0PWDSGCR 32-bit
0xFFF20508 ADCA0PWDSGCRL 16-bit
0xFFF20508 ADCA0PWDSGCRLL
0xFFF20518 ADCA0PWDSGSEFCR 32-bit wo
0xFFF20518 ADCA0PWDSGSEFCRL 16-bit wo
0xFFF20518 ADCA0PWDSGSEFCRLL wo
{0xFFF21000+4i} ADCA1VCR{i:02} 32-bit (i=0..23)
{0xFFF21000+4i} ADCA1VCR{i:02}L 16-bit (i=0..23)
{0xFFF21000+4i} ADCA1VCR{i:02}LL (i=0..23)
{0xFFF21001+4i} ADCA1VCR{i:02}LH (i=0..23)
0xFFF210F4 ADCA1PWDVCR 32-bit ro
0xFFF210F4 ADCA1PWDVCRL 16-bit ro
0xFFF210F4 ADCA1PWDVCRLL ro
0xFFF210F5 ADCA1PWDVCRLH ro
0xFFF21100 ADCA1DR00 32-bit ro
0xFFF21100 ADCA1DR00L 16-bit ro
0xFFF21102 ADCA1DR00H 16-bit ro
0xFFF21104 ADCA1DR02 32-bit ro
0xFFF21104 ADCA1DR02L 16-bit ro
0xFFF21106 ADCA1DR02H 16-bit ro
0xFFF21108 ADCA1DR04 32-bit ro
0xFFF21108 ADCA1DR04L 16-bit ro
0xFFF2110A ADCA1DR04H 16-bit ro
0xFFF2110C ADCA1DR06 32-bit ro
0xFFF2110C ADCA1DR06L 16-bit ro
0xFFF2110E ADCA1DR06H 16-bit ro
0xFFF21110 ADCA1DR08 32-bit ro
0xFFF21110 ADCA1DR08L 16-bit ro
0xFFF21112 ADCA1DR08H 16-bit ro
0xFFF21114 ADCA1DR10 32-bit ro
0xFFF21114 ADCA1DR10L 16-bit ro
0xFFF21116 ADCA1DR10H 16-bit ro
0xFFF21118 ADCA1DR12 32-bit ro
0xFFF21118 ADCA1DR12L 16-bit ro
0xFFF2111A ADCA1DR12H 16-bit ro
0xFFF2111C ADCA1DR14 32-bit ro
0xFFF2111C ADCA1DR14L 16-bit ro
0xFFF2111E ADCA1DR14H 16-bit ro
0xFFF21120 ADCA1DR16 32-bit ro
0xFFF21120 ADCA1DR16L 16-bit ro
0xFFF21122 ADCA1DR16H 16-bit ro
0xFFF21124 ADCA1DR18 32-bit ro
0xFFF21124 ADCA1DR18L 16-bit ro
0xFFF21126 ADCA1DR18H 16-bit ro
0xFFF21128 ADCA1DR20 32-bit ro
0xFFF21128 ADCA1DR20L 16-bit ro
0xFFF2112A ADCA1DR20H 16-bit ro
0xFFF2112C ADCA1DR22 32-bit ro
0xFFF2112C ADCA1DR22L 16-bit ro
0xFFF2112E ADCA1DR22H 16-bit ro
0xFFF21178 ADCA1PWDTSNDR 32-bit ro
0xFFF2117A ADCA1PWDTSNDRH 16-bit ro
{0xFFF21200+4i} ADCA1DIR{i:02} 32-bit ro (i=0..23)
0xFFF212F4 ADCA1PWDDIR 32-bit ro
0xFFF21300 ADCA1ADHALTR 32-bit wo
0xFFF21300 ADCA1ADHALTRL 16-bit wo
0xFFF21300 ADCA1ADHALTRLL wo
0xFFF21304 ADCA1ADCR 32-bit
0xFFF21304 ADCA1ADCRL 16-bit
0xFFF21304 ADCA1ADCRLL
0xFFF21308 ADCA1SGSTR 32-bit ro
0xFFF21308 ADCA1SGSTRL 16-bit ro
0xFFF21334 ADCA1SFTCR 32-bit
0xFFF21334 ADCA1SFTCRL 16-bit
0xFFF21334 ADCA1SFTCRLL
{0xFFF21338+4i} ADCA1ULLMTBR{i} 32-bit (i=0..2)
{0xFFF21338+4i} ADCA1ULLMTBR{i}L 16-bit (i=0..2)
{0xFFF2133A+4i} ADCA1ULLMTBR{i}H 16-bit (i=0..2)
0xFFF21344 ADCA1ECR 32-bit wo
0xFFF21344 ADCA1ECRL 16-bit wo
0xFFF21344 ADCA1ECRLL wo
0xFFF21348 ADCA1ULER 32-bit ro
0xFFF21348 ADCA1ULERL 16-bit ro
0xFFF21348 ADCA1ULERLL ro
0xFFF21349 ADCA1ULERLH ro
0xFFF2134C ADCA1OWER 32-bit ro
0xFFF2134C ADCA1OWERL 16-bit ro
0xFFF2134C ADCA1OWERLL ro
0xFFF21350 ADCA1DGCTL0 32-bit
0xFFF21350 ADCA1DGCTL0L 16-bit
0xFFF21350 ADCA1DGCTL0LL
0xFFF21354 ADCA1DGCTL1 32-bit
0xFFF21354 ADCA1DGCTL1L 16-bit
0xFFF21358 ADCA1PDCTL1 32-bit
0xFFF21358 ADCA1PDCTL1L 16-bit
0xFFF2135C ADCA1PDCTL2 32-bit
0xFFF2135C ADCA1PDCTL2L 16-bit
0xFFF2135C ADCA1PDCTL2LL
0xFFF21380 ADCA1SMPCR 32-bit
0xFFF21380 ADCA1SMPCRL 16-bit
0xFFF21380 ADCA1SMPCRLL
0xFFF21388 ADCA1EMU
{0xFFF21400+0x40*i} ADCA1SGSTCR{i} 32-bit wo (i=1..3)
{0xFFF21400+0x40*i} ADCA1SGSTCR{i}L 16-bit wo (i=1..3)
{0xFFF21400+0x40*i} ADCA1SGSTCR{i}LL wo (i=1..3)
{0xFFF21408+0x40*i} ADCA1SGCR{i} 32-bit (i=1..3)
{0xFFF21408+0x40*i} ADCA1SGCR{i}L 16-bit (i=1..3)
{0xFFF21408+0x40*i} ADCA1SGCR{i}LL (i=1..3)
{0xFFF2140C+0x40*i} ADCA1SGVCSP{i} 32-bit (i=1..3)
{0xFFF2140C+0x40*i} ADCA1SGVCSP{i}L 16-bit (i=1..3)
{0xFFF2140C+0x40*i} ADCA1SGVCSP{i}LL (i=1..3)
{0xFFF21410+0x40*i} ADCA1SGVCEP{i} 32-bit (i=1..3)
{0xFFF21410+0x40*i} ADCA1SGVCEP{i}L 16-bit (i=1..3)
{0xFFF21410+0x40*i} ADCA1SGVCEP{i}LL (i=1..3)
{0xFFF21414+0x40*i} ADCA1SGMCYCR{i} 32-bit (i=1..3)
{0xFFF21414+0x40*i} ADCA1SGMCYCR{i}L 16-bit (i=1..3)
{0xFFF21414+0x40*i} ADCA1SGMCYCR{i}LL (i=1..3)
{0xFFF21418+0x40*i} ADCA1SGSEFCR{i} 32-bit wo (i=1..3)
{0xFFF21418+0x40*i} ADCA1SGSEFCR{i}L 16-bit wo (i=1..3)
{0xFFF21418+0x40*i} ADCA1SGSEFCR{i}LL wo (i=1..3)
{0xFFF2141C+0x40*i} ADCA1SGTSEL{i} 32-bit (i=1..3)
{0xFFF2141C+0x40*i} ADCA1SGTSEL{i}L 16-bit (i=1..3)
0xFFF21508 ADCA1PWDSGCR 32-bit
0xFFF21508 ADCA1PWDSGCRL 16-bit
0xFFF21508 ADCA1PWDSGCRLL
0xFFF21518 ADCA1PWDSGSEFCR 32-bit wo
0xFFF21518 ADCA1PWDSGSEFCRL 16-bit wo
0xFFF21518 ADCA1PWDSGSEFCRLL wo
0xFFF50000 CVMF 32-bit
0xFFF50004 CVMDE 32-bit ro
0xFFF50014 CVMDIAG 32-bit
0xFFF50100 PROTCMDCVM 32-bit wo
0xFFF50104 PROTSCVM 32-bit ro
{0xFFF70000+0x1000*i} DCRA{i}CIN 32-bit (i=0..3)
{0xFFF70004+0x1000*i} DCRA{i}COUT 32-bit (i=0..3)
{0xFFF70020+0x1000*i} DCRA{i}CTL (i=0..3)
0xFFF78000 KR0KRM
  [n] KR0KRM{n} (n=0..7)
0xFFF80000 PROTCMD0 32-bit wo
0xFFF80004 PROTS0 32-bit ro
0xFFF80100 STBC0PSC 32-bit
0xFFF80110 STBC0STPT 32-bit
0xFFF80200 WDTNMIF 32-bit ro
0xFFF80208 WDTNMIFC 32-bit wo
0xFFF80300 FEINTF 32-bit ro
0xFFF80304 FEINTFMSK 32-bit
0xFFF80308 FEINTFC 32-bit wo
0xFFF80400 WUF0 32-bit ro
0xFFF80404 WUFMSK0 32-bit
0xFFF80408 WUFC0 32-bit wo
0xFFF80520 WUF20 32-bit ro
0xFFF80524 WUFMSK20 32-bit
0xFFF80528 WUFC20 32-bit wo
0xFFF80760 RESF 32-bit ro
0xFFF80768 RESFC 32-bit wo
0xFFF80860 RESFR 32-bit ro
0xFFF80868 RESFCR 32-bit wo
0xFFF80980 VLVF 32-bit ro
0xFFF80988 VLVFC 32-bit wo
0xFFF80A00 LVICNT 32-bit
0xFFF80A04 SWRESA 32-bit wo
0xFFF80B00 IOHOLD 32-bit
0xFFF81000 ROSCE 32-bit
0xFFF81004 ROSCS 32-bit ro
0xFFF81018 ROSCSTPM 32-bit
0xFFF81100 MOSCE 32-bit
0xFFF81104 MOSCS 32-bit ro
0xFFF81108 MOSCC 32-bit
0xFFF8110C MOSCST 32-bit
0xFFF81118 MOSCSTPM 32-bit
0xFFF81200 SOSCE 32-bit
0xFFF81204 SOSCS 32-bit ro
0xFFF8120C SOSCST 32-bit
0xFFF82800 FOUTDIV 32-bit
0xFFF82804 FOUTSTAT 32-bit ro
0xFFF88000 PROTCMD1 32-bit wo
0xFFF88004 PROTS1 32-bit ro
0xFFF88110 WUF_ISO0 32-bit ro
0xFFF88114 WUFMSK_ISO0 32-bit
0xFFF88118 WUFC_ISO0 32-bit wo
0xFFF89000 PLLE 32-bit
0xFFF89004 PLLS 32-bit ro
0xFFF89008 PLLC 32-bit
{0xFFF8C000+0x1000*i} CLMA{i}CTL0 (i=0..2)
{0xFFF8C008+0x1000*i} CLMA{i}CMPL 16-bit (i=0..2)
{0xFFF8C00C+0x1000*i} CLMA{i}CMPH 16-bit (i=0..2)
{0xFFF8C010+0x1000*i} CLMA{i}PCMD wo (i=0..2)
{0xFFF8C014+0x1000*i} CLMA{i}PS ro (i=0..2)
{0xFFF8C018+0x1000*i} CLMA{i}EMU0 (i=0..2)
0xFFF8C100 CLMATEST 32-bit
0xFFF8C104 CLMATESTS 32-bit ro
0xFFF8C200 PROTCMDCLMA 32-bit wo
0xFFF8C204 PROTSCLMA 32-bit ro
0xFFFF8200 BSC 16-bit
0xFFFF8202 DEC 16-bit
0xFFFF8208 DWC 16-bit
0xFFFF820C DHC 16-bit
0xFFFF8210 AWC 16-bit
0xFFFF8214 ICC 16-bit
0xFFFF8300 DTRC0
  [7] DTRC0ERR, [0] DTRC0ADS
0xFFFF8304 DMCM0 16-bit
{0xFFFF8314+0x30*i} DSA{i} 32-bit (i=0..7)
{0xFFFF8314+0x30*i} DSA{i}L 16-bit (i=0..7)
{0xFFFF8316+0x30*i} DSA{i}H 16-bit (i=0..7)
{0xFFFF8324+0x30*i} DDA{i} 32-bit (i=0..7)
{0xFFFF8324+0x30*i} DDA{i}L 16-bit (i=0..7)
{0xFFFF8326+0x30*i} DDA{i}H 16-bit (i=0..7)
{0xFFFF8332+0x30*i} DTC{i} 16-bit (i=0..7)
{0xFFFF8338+0x30*i} DTCT{i} 16-bit (i=0..7)
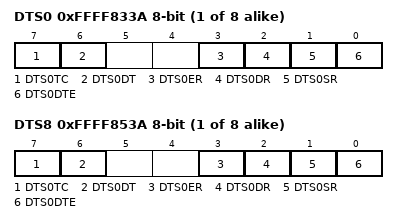
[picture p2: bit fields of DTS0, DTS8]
{0xFFFF833A+0x30*i} DTS{i} (i=0..7)
  [7] DTS{i}TC, [6] DTS{i}DT, [3] DTS{i}ER ro, [2] DTS{i}DR ro, [1] DTS{i}SR, [0] DTS{i}DTE
{0xFFFF8394+0x30*i} DSA{i} 32-bit (i=8..15)
{0xFFFF8394+0x30*i} DSA{i}L 16-bit (i=8..15)
{0xFFFF8396+0x30*i} DSA{i}H 16-bit (i=8..15)
{0xFFFF83A4+0x30*i} DDA{i} 32-bit (i=8..15)
{0xFFFF83A4+0x30*i} DDA{i}L 16-bit (i=8..15)
{0xFFFF83A6+0x30*i} DDA{i}H 16-bit (i=8..15)
{0xFFFF83B2+0x30*i} DTC{i} 16-bit (i=8..15)
{0xFFFF83B8+0x30*i} DTCT{i} 16-bit (i=8..15)
{0xFFFF83BA+0x30*i} DTS{i} (i=8..15)
  fields as DTS0
{0xFFFF8B00+2i} DTFR{i} 16-bit (i=0..15)
0xFFFF8B40 DRQCLR 16-bit
0xFFFF8B44 DRQSTR 16-bit ro
0xFFFF9000 ICTAUD0I0 16-bit
0xFFFF9000 ICTAUD0I0L
  [7] MKCSIH2IC_1, [7] MKTAUD0I0, [6] TBCSIH2IC_1, [6] TBTAUD0I0, [2] P2CSIH2IC_1, [2] P2TAUD0I0, [1] P1CSIH2IC_1, [1] P1TAUD0I0, [0] P0CSIH2IC_1, [0] P0TAUD0I0
0xFFFF9000 ICCSIH2IC_1 16-bit
0xFFFF9000 ICCSIH2ICL_1
0xFFFF9001 ICTAUD0I0H
  [7] CTCSIH2IC_1 ro, [7] CTTAUD0I0 ro, [4] RFCSIH2IC_1, [4] RFTAUD0I0
0xFFFF9001 ICCSIH2ICH_1
0xFFFF9002 ICTAUD0I2 16-bit
0xFFFF9002 ICTAUD0I2L
  [7] MKCSIH3IC_1, [7] MKTAUD0I2, [6] TBCSIH3IC_1, [6] TBTAUD0I2, [2] P2CSIH3IC_1, [2] P2TAUD0I2, [1] P1CSIH3IC_1, [1] P1TAUD0I2, [0] P0CSIH3IC_1, [0] P0TAUD0I2
0xFFFF9002 ICCSIH3IC_1 16-bit

## Notices in the file
Copyright(C) 2015 Renesas
